# ATSAMD21E15BU device description
Architecture: CORTEX-M0PLUS; Family: SAMD; Series: SAMD21
Registers are 32-bit, read-write, reset 0x0 unless marked. A register's access mark holds for its fields unless they carry their own. Offsets are from the block's base; [hi:lo] are bit positions; {n}, {i} and the like mark numbered series; 'fields as' and 'values as' point back to an identical list.

## AUX3_FUSES — Non-Volatile Fuses
Instances: AUX3_FUSES 0x0080A000 in fuses
0x0C AUX3_WORD_3 ro reset not defined — AUX3 Page Word 3
  [31:0] SERIAL_NUMBER_3 — Serial Number word 3
{0x0+4i} AUX3_WORD_{i} ro reset not defined (i=16..18) — AUX3 Page Word {i}
  [31:0] SERIAL_NUMBER_{i-16} — Serial Number words 2-0 bits {32i-481}:{32i-512}

## OTP4_FUSES — Non-Volatile Fuses
Instances: OTP4_FUSES 0x00806020 in fuses
0x00 OTP4_WORD_0 ro reset not defined — OTP4 Page Word 0
  [31:27] ADC_LINEARITY_0 — ADC Linearity bits 4:0
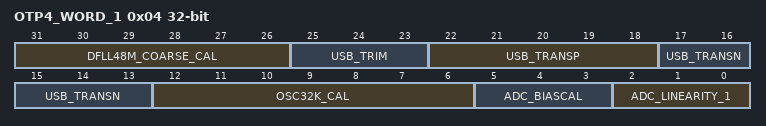
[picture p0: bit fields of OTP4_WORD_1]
0x04 OTP4_WORD_1 ro reset not defined — OTP4 Page Word 1
  [31:26] DFLL48M_COARSE_CAL — DFLL48M Coarse Calibration
  [25:23] USB_TRIM — USB pad Trim calibration
  [22:18] USB_TRANSP — USB pad Transp calibration
  [17:13] USB_TRANSN — USB pad Transn calibration
  [12:6] OSC32K_CAL — OSC32K Calibration
  [5:3] ADC_BIASCAL — ADC Bias Calibration
  [2:0] ADC_LINEARITY_1 — ADC Linearity bits 7:5
0x08 OTP4_WORD_2 ro reset not defined — OTP4 Page Word 2
  [9:0] DFLL48M_FINE_CAL — DFLL48M Fine Calibration

## TEMP_LOG_FUSES — Non-Volatile Fuses
Instances: TEMP_LOG_FUSES 0x00806030 in fuses
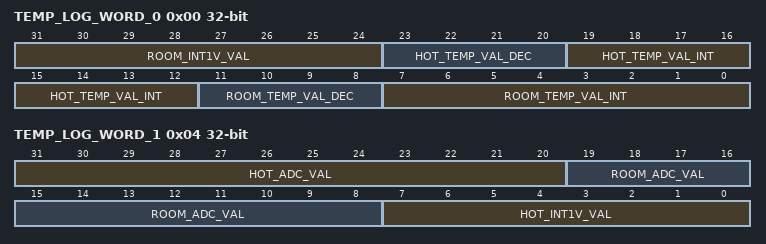
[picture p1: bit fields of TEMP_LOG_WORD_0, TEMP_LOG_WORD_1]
0x00 TEMP_LOG_WORD_0 ro reset not defined — TEMP_LOG Page Word 0
  [31:24] ROOM_INT1V_VAL — 2's complement of the internal 1V reference drift at room temperature (versus a 1.0 centered value)
  [23:20] HOT_TEMP_VAL_DEC — Decimal part of hot temperature
  [19:12] HOT_TEMP_VAL_INT — Integer part of hot temperature in oC
  [11:8] ROOM_TEMP_VAL_DEC — Decimal part of room temperature
  [7:0] ROOM_TEMP_VAL_INT — Integer part of room temperature in oC
0x04 TEMP_LOG_WORD_1 ro reset not defined — TEMP_LOG Page Word 1
  [31:20] HOT_ADC_VAL — 12-bit ADC conversion at hot temperature
  [19:8] ROOM_ADC_VAL — 12-bit ADC conversion at room temperature
  [7:0] HOT_INT1V_VAL — 2's complement of the internal 1V reference drift at hot temperature (versus a 1.0 centered value)

## USER_FUSES — Non-Volatile Fuses
Instances: USER_FUSES 0x00804000 in fuses
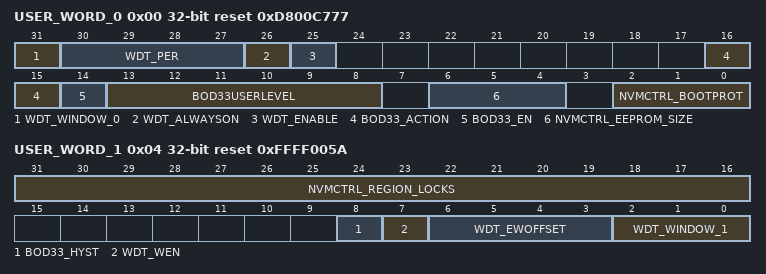
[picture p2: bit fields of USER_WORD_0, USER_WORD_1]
0x00 USER_WORD_0 reset 0xD800C777 — USER Page Word 0
  [31] WDT_WINDOW_0 — WDT Window bit 0
  [30:27] WDT_PER — WDT Period
    0=CYC8 (8 clock cycles); 1=CYC16 (16 clock cycles); 2=CYC32 (32 clock cycles); 3=CYC64 (64 clock cycles); 4=CYC128 (128 clock cycles); 5=CYC256 (256 clock cycles); 6=CYC512 (512 clock cycles); 7=CYC1024 (1024 clock cycles); 8=CYC2048 (2048 clock cycles); 9=CYC4096 (4096 clock cycles); 10=CYC8192 (8192 clock cycles); 11=CYC16384 (16384 clock cycles)
  [26] WDT_ALWAYSON
    0=DISABLED (WDT is enabled and disabled through ENABLE bit); 1=ENABLED (WDT is enabled and can only be disabled by a power-on reset)
  [25] WDT_ENABLE
    0=DISABLED (WDT is disabled); 1=ENABLED (WDT is enabled)
  [16:15] BOD33_ACTION
    0=NONE (No action); 1=RESET (BOD33 generates a reset); 2=INT (BOD33 generates an interrupt)
  [14] BOD33_EN — BOD33 Enable
    0=DISABLED (BOD33 is disabled); 1=ENABLED (BOD33 is enableD)
  [13:8] BOD33USERLEVEL
  [6:4] NVMCTRL_EEPROM_SIZE — EEPROM Size
    0=SIZE_16384BYTES (16384 Bytes); 1=SIZE_8192BYTES (8192 Bytes); 2=SIZE_4096BYTES (4096 Bytes); 3=SIZE_2048BYTES (2048 Bytes); 4=SIZE_1024BYTES (1024 Bytes); 5=SIZE_512BYTES (512 Bytes); 6=SIZE_256BYTES (256 Bytes); 7=SIZE_0BYTES (0 Bytes)
  [2:0] NVMCTRL_BOOTPROT — Bootloader Size
    0=SIZE_32768BYTES (32768 Bytes); 1=SIZE_16384BYTES (16384 Bytes); 2=SIZE_8192BYTES (8192 Bytes); 3=SIZE_4096BYTES (4096 Bytes); 4=SIZE_2048BYTES (2048 Bytes); 5=SIZE_1024BYTES (1024 Bytes); 6=SIZE_512BYTES (512 Bytes); 7=SIZE_0BYTES (0 Bytes)
0x04 USER_WORD_1 reset 0xFFFF005A — USER Page Word 1
  [31:16] NVMCTRL_REGION_LOCKS — NVM Region Locks
  [8] BOD33_HYST — BOD33 Hysteresis
    0=DISABLED (No hysteresis); 1=ENABLED (Hysteresis enabled)
  [7] WDT_WEN — WDT Window Mode Enable
    0=DISABLED (Window mode is disabled); 1=ENABLED (Window mode is enabled)
  [6:3] WDT_EWOFFSET — WDT Early Warning Offset
    values as USER_WORD_0.WDT_PER
  [2:0] WDT_WINDOW_1 — WDT Window bits 3:1
Value list USER_FUSES_NVMCTRL__BOOTPROT: 7=0 Bytes; 6=512 Bytes; 5=1K (1024 Bytes); 4=2K (2048 Bytes); 3=4K (4096 Bytes); 2=8K (8192 Bytes); 1=16K (16384 Bytes); 0=32K (32768 Bytes)
Value list USER_FUSES_NVMCTRL__EEPROM_SIZE: 7=0 Bytes; 6=256 Bytes; 5=512 Bytes; 4=1K (1024 Bytes); 3=2K (2048 Bytes); 2=4K (4096 Bytes); 1=8K (8192 Bytes); 0=16K (16384 Bytes)
Value list SYSCTRL_BOD33__ACTION: 0=NONE (No action); 1=RESET (The BOD33 generates a reset); 2=INTERRUPT (The BOD33 generates an interrupt)
Value list WDT_CONFIG__PER: 0=8 clock cycles; 1=16 clock cycles; 2=32 clock cycles; 3=64 clock cycles; 4=128 clock cycles; 5=256 clock cycles; 6=512 clock cycles; 7=1K (1024 clock cycles); 8=2K (2048 clock cycles); 9=4K (4096 clock cycles); 10=8K (8192 clock cycles); 11=16K (16384 clock cycles)

## Notices in the file
Copyright (c) 2018 Microchip Technology Inc.
SPDX-License-Identifier: Apache-2.0
Licensed under the Apache License, Version 2.0 (the "License");
you may not use this file except in compliance with the License.
You may obtain a copy of the License at
http://www.apache.org/licenses/LICENSE-2.0
Unless required by applicable law or agreed to in writing, software
distributed under the License is distributed on an "AS IS" BASIS,
WITHOUT WARRANTIES OR CONDITIONS OF ANY KIND, either express or implied.
See the License for the specific language governing permissions and
limitations under the License.
